# AC30M1X64 register map
Vendor: ABOV Semiconductor Co., Ltd.; File version: 1.0.0
CPU: CM0 r1p0, little endian, no MPU, no FPU, 2 interrupt priority bits
Registers are 32-bit, read-write, reset 0x0 unless marked. A register's access mark holds for its fields unless they carry their own. Offsets are from the block's base; [hi:lo] are bit positions.

## WDT — WATCH-DOG TIMER
Base 0x40000200
0x00 LR — Watchdog Timer Load Register
0x04 CNT reset 0xFFFF — Watchdog Timer Current Counter Register
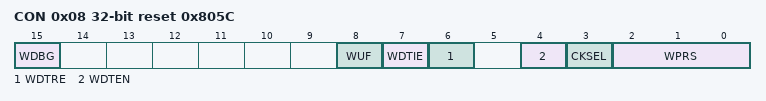
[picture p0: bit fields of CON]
0x08 CON reset 0x805C — Watchdog Timer Control Register
  [15] WDBG — WDT operation in debug mode
  [8] WUF — WDT underflow flag
  [7] WDTIE — WDT interrupt enable
  [6] WDTRE — WDT interrupt reset
  [4] WDTEN — WDT counter enable
  [3] CKSEL — WDTCLKIN clock source select
  [2:0] WPRS — counter prescaler

## T0 — 16-BIT TIMER
Base 0x40003000
Same registers: T1 0x40003020, T2 0x40003040, T3 0x40003060
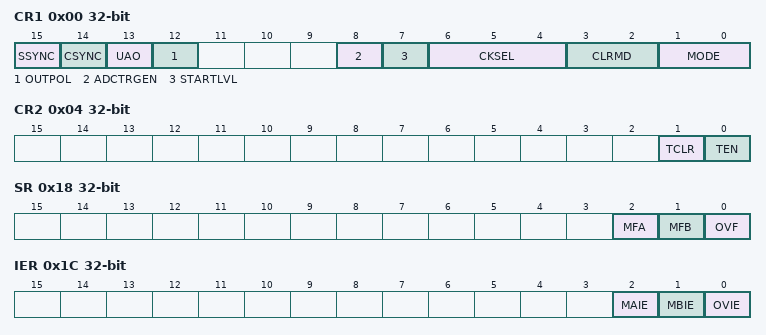
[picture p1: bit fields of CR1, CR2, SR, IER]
0x00 CR1 — Timer n Control Register 1
  [15] SSYNC — Synchronize start counter with other synchronized timers
  [14] CSYNC — Synchronize clear counter with other synchronized tip
  [13] UAO — Select GRA,GRB Update mode
  [12] OUTPOL — timer output polarity
  [8] ADCTRGEN
  [7] STARTLVL
  [6:4] CKSEL — counter clock source select
  [3:2] CLRMD — clear select when capture mode
  [1:0] MODE — Timer operation mode control
0x04 CR2 — Timer n Control Register 2
  [1] TCLR — Timer register clear
  [0] TEN — Timer enable bit
0x08 PRS — Timer n Prescaler Register
  [9:0] PRS — Prescaler value of count clock
0x0C GRA — Timer n General Register A
  [15:0] GRA
0x10 GRB — Timer n General Register B
  [15:0] GRB
0x14 CNT — Timer n Count Register
  [15:0] CNT
0x18 SR — Timer n Status Register
  [2] MFA — GRA Match flag
  [1] MFB — GRB Match flag
  [0] OVF — counter overflow flag
0x1C IER — Timer n Interrupt Enable Register
  [2] MAIE — GRA Match interrupt enable
  [1] MBIE — GRB Match interrupt enable
  [0] OVIE — Counter overflow interrupt enable

## FRT — Free-run Timer
Base 0x40000600
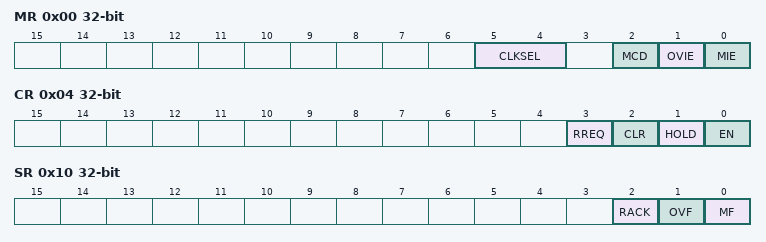
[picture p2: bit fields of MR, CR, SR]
0x00 MR — FRT Mode Register
  [5:4] CLKSEL — FRT Counter clock source control
  [2] MCD — Counter Match Clear Disable bit
  [1] OVIE — Over Flow Interrupt Enable bit
  [0] MIE — Match Interrupt Enable bit
0x04 CR — FRT Control Register
  [3] RREQ — FRT Counter read request bit
  [2] CLR — FRT Counter register clear bit
  [1] HOLD — FRT Counter register hold bit
  [0] EN — FRT enable bit
0x08 PER — FRTPER FRT Period Match Register
0x0C CNT — FRTCNT FRT Counter Register
0x10 SR (reset mask 0x3) — FRTSR FRT Status Register
  [2] RACK — Read Counter Acknowledge bit
  [1] OVF — Overflow Interrupt Flag
  [0] MF — Interrupt Flag

## U0 — UNIVERSAL ASYNCHRONOUS RECEIVER/TRANSMITTER
Base 0x40008000
Same registers: U1 0x40008100
0x00 RBR ro — Receive Buffer Register
  [7:0] RBR — recevied/transmit data
0x00 THR wo — Transmit Data Hold Register
  [7:0] THR — received/transmit data
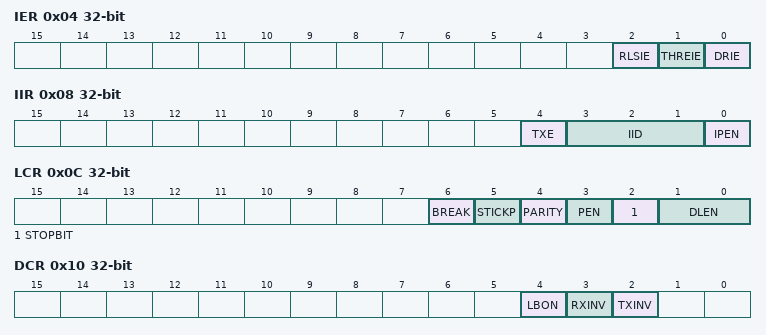
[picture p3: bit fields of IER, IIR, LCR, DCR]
0x04 IER — UART Interrupt Enable Register
  [2] RLSIE — receiver line status interrupt enable
  [1] THREIE — Transmit holding register empty interrupt enable
  [0] DRIE — Data receive interrupt enable
0x08 IIR — UART Interrupt ID Register
  [4] TXE — Interrupt source ID
  [3:1] IID — Interrupt source ID
  [0] IPEN — Interrupt pending bit
0x0C LCR — UART Line Control Register
  [6] BREAK
  [5] STICKP — STICK
  [4] PARITY
  [3] PEN — parity bit transfer enable
  [2] STOPBIT
  [1:0] DLEN — Data length in one transfer word
0x10 DCR — UART Data Control Register
  [4] LBON — Local loopback test mode enable
  [3] RXINV — Rx Data Inversion selection
  [2] TXINV — TX Data Inversion selection
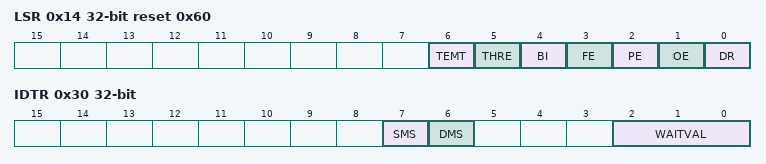
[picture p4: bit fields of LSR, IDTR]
0x14 LSR reset 0x60 — UART Line Status Register
  [6] TEMT — Transmit empty
  [5] THRE — Transmit holding register empty
  [4] BI — break condition indication bit
  [3] FE — frame error
  [2] PE — parity error
  [1] OE — overrun error
  [0] DR — Data recevied
0x20 BDR — Baud rate Divisor Latch Register
  [15:0] BDR — baudrate setting
0x24 BFR — Baud rate Fraction Counter Register
  [7:0] BFR — Fraction counter value
0x30 IDTR — Inter-frame Delay Time Register
  [7] SMS — Start Bit Multi sampling enable
  [6] DMS — Data Bit Multi sampling enable
  [2:0] WAITVAL — wait time is decied by this value
